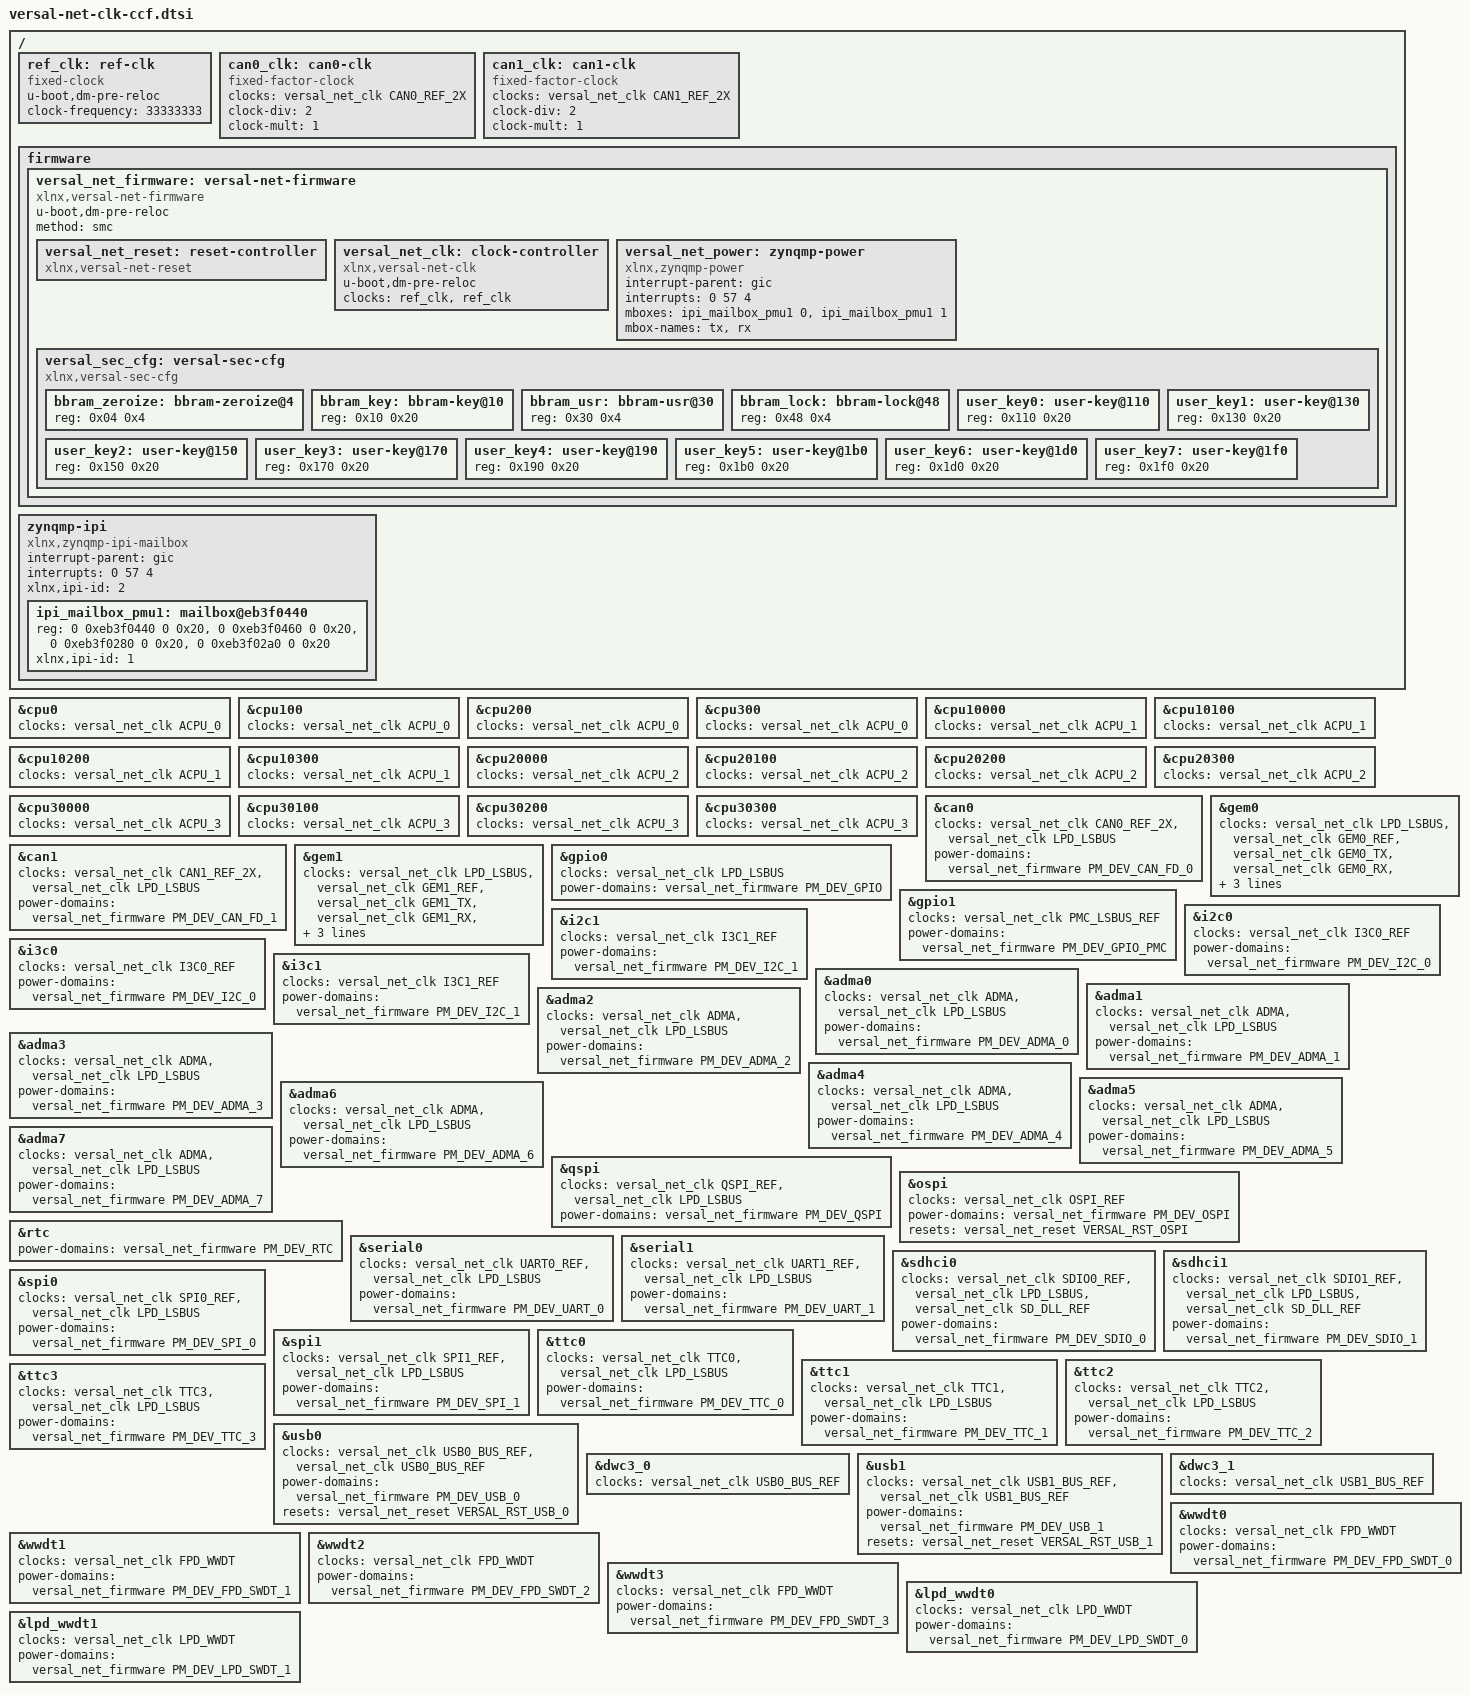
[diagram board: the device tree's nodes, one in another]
// SPDX-License-Identifier: GPL-2.0
/*
 * dts file for Xilinx Versal with PM
 *
 * Copyright (C) 2022, Xilinx, Inc.
 * Copyright (C) 2022, Advanced Micro Devices, Inc.
 *
 * Michal Simek <michal.simek@amd.com>
 */

#include <dt-bindings/clock/xlnx-versal-net-clk.h>
#include <dt-bindings/power/xlnx-versal-net-power.h>
#include <dt-bindings/reset/xlnx-versal-net-resets.h>

/ {
	ref_clk: ref-clk {
		u-boot,dm-pre-reloc;
		compatible = "fixed-clock";
		#clock-cells = <0>;
		clock-frequency = <33333333>;
	};

	can0_clk: can0-clk {
		#clock-cells = <0>;
		compatible = "fixed-factor-clock";
		clocks = <&versal_net_clk CAN0_REF_2X>;
		clock-div = <2>;
		clock-mult = <1>;
	};

	can1_clk: can1-clk {
		#clock-cells = <0>;
		compatible = "fixed-factor-clock";
		clocks = <&versal_net_clk CAN1_REF_2X>;
		clock-div = <2>;
		clock-mult = <1>;
	};

	firmware {
		versal_net_firmware: versal-net-firmware {
			compatible = "xlnx,versal-net-firmware";
			u-boot,dm-pre-reloc;
			method = "smc";
			#power-domain-cells = <1>;

			versal_net_reset: reset-controller {
				compatible = "xlnx,versal-net-reset";
				#reset-cells = <1>;
			};

			versal_net_clk: clock-controller {
				u-boot,dm-pre-reloc;
				#clock-cells = <1>;
				compatible = "xlnx,versal-net-clk";
				clocks = <&ref_clk>, <&ref_clk>;
				clock-names = "ref_clk", "pl_alt_ref_clk";
			};

			versal_net_power: zynqmp-power { /* untested */
				compatible = "xlnx,zynqmp-power";
				interrupt-parent = <&gic>;
				interrupts = <0 57 4>;
				mboxes = <&ipi_mailbox_pmu1 0>,
					 <&ipi_mailbox_pmu1 1>;
				mbox-names = "tx", "rx";
			};

			versal_sec_cfg: versal-sec-cfg { /* untested */
				compatible = "xlnx,versal-sec-cfg";
				#address-cells = <1>;
				#size-cells = <1>;

				bbram_zeroize: bbram-zeroize@4 {
					reg = <0x04 0x4>;
				};

				bbram_key: bbram-key@10 {
					reg = <0x10 0x20>;
				};

				bbram_usr: bbram-usr@30 {
					reg = <0x30 0x4>;
				};

				bbram_lock: bbram-lock@48 {
					reg = <0x48 0x4>;
				};

				user_key0: user-key@110 {
					reg = <0x110 0x20>;
				};

				user_key1: user-key@130 {
					reg = <0x130 0x20>;
				};

				user_key2: user-key@150 {
					reg = <0x150 0x20>;
				};

				user_key3: user-key@170 {
					reg = <0x170 0x20>;
				};

				user_key4: user-key@190 {
					reg = <0x190 0x20>;
				};

				user_key5: user-key@1b0 {
					reg = <0x1b0 0x20>;
				};

				user_key6: user-key@1d0 {
					reg = <0x1d0 0x20>;
				};

				user_key7: user-key@1f0 {
					reg = <0x1f0 0x20>;
				};
			};
		};
	};

	zynqmp-ipi {
		compatible = "xlnx,zynqmp-ipi-mailbox";
		interrupt-parent = <&gic>;
		interrupts = <0 57 4>;
		xlnx,ipi-id = <2>;
		#address-cells = <2>;
		#size-cells = <2>;
		ranges;

		ipi_mailbox_pmu1: mailbox@eb3f0440 {
			reg = <0 0xeb3f0440 0 0x20>,
			      <0 0xeb3f0460 0 0x20>,
			      <0 0xeb3f0280 0 0x20>,
			      <0 0xeb3f02a0 0 0x20>;
			reg-names = "local_request_region", "local_response_region",
				    "remote_request_region", "remote_response_region";
			#mbox-cells = <1>;
			xlnx,ipi-id = <1>;
		};
	};
};

&cpu0 {
	clocks = <&versal_net_clk ACPU_0>;
};

&cpu100 {
	clocks = <&versal_net_clk ACPU_0>;
};

&cpu200 {
	clocks = <&versal_net_clk ACPU_0>;
};

&cpu300 {
	clocks = <&versal_net_clk ACPU_0>;
};

&cpu10000 {
	clocks = <&versal_net_clk ACPU_1>;
};

&cpu10100 {
	clocks = <&versal_net_clk ACPU_1>;
};

&cpu10200 {
	clocks = <&versal_net_clk ACPU_1>;
};

&cpu10300 {
	clocks = <&versal_net_clk ACPU_1>;
};

&cpu20000 {
	clocks = <&versal_net_clk ACPU_2>;
};

&cpu20100 {
	clocks = <&versal_net_clk ACPU_2>;
};

&cpu20200 {
	clocks = <&versal_net_clk ACPU_2>;
};

&cpu20300 {
	clocks = <&versal_net_clk ACPU_2>;
};

&cpu30000 {
	clocks = <&versal_net_clk ACPU_3>;
};

&cpu30100 {
	clocks = <&versal_net_clk ACPU_3>;
};

&cpu30200 {
	clocks = <&versal_net_clk ACPU_3>;
};

&cpu30300 {
	clocks = <&versal_net_clk ACPU_3>;
};

&can0 {
	clocks = <&versal_net_clk CAN0_REF_2X>, <&versal_net_clk LPD_LSBUS>;
	power-domains = <&versal_net_firmware PM_DEV_CAN_FD_0>;
};

&can1 {
	clocks = <&versal_net_clk CAN1_REF_2X>, <&versal_net_clk LPD_LSBUS>;
	power-domains = <&versal_net_firmware PM_DEV_CAN_FD_1>;
};

&gem0 {
	clocks = <&versal_net_clk LPD_LSBUS>,
		 <&versal_net_clk GEM0_REF>, <&versal_net_clk GEM0_TX>,
		 <&versal_net_clk GEM0_RX>, <&versal_net_clk GEM_TSU>;
	power-domains = <&versal_net_firmware PM_DEV_GEM_0>;
};

&gem1 {
	clocks = <&versal_net_clk LPD_LSBUS>,
		 <&versal_net_clk GEM1_REF>, <&versal_net_clk GEM1_TX>,
		 <&versal_net_clk GEM1_RX>, <&versal_net_clk GEM_TSU>;
	power-domains = <&versal_net_firmware PM_DEV_GEM_1>;
};

&gpio0 {
	clocks = <&versal_net_clk LPD_LSBUS>;
	power-domains = <&versal_net_firmware PM_DEV_GPIO>;
};

&gpio1 {
	clocks = <&versal_net_clk PMC_LSBUS_REF>;
	power-domains = <&versal_net_firmware PM_DEV_GPIO_PMC>;
};

&i2c0 {
	clocks = <&versal_net_clk I3C0_REF>;
	power-domains = <&versal_net_firmware PM_DEV_I2C_0>;
};

&i2c1 {
	clocks = <&versal_net_clk I3C1_REF>;
	power-domains = <&versal_net_firmware PM_DEV_I2C_1>;
};

&i3c0 {
	clocks = <&versal_net_clk I3C0_REF>;
	power-domains = <&versal_net_firmware PM_DEV_I2C_0>;
};

&i3c1 {
	clocks = <&versal_net_clk I3C1_REF>;
	power-domains = <&versal_net_firmware PM_DEV_I2C_1>;
};

&adma0 {
	clocks = <&versal_net_clk ADMA>, <&versal_net_clk LPD_LSBUS>;
	power-domains = <&versal_net_firmware PM_DEV_ADMA_0>;
};

&adma1 {
	clocks = <&versal_net_clk ADMA>, <&versal_net_clk LPD_LSBUS>;
	power-domains = <&versal_net_firmware PM_DEV_ADMA_1>;
};

&adma2 {
	clocks = <&versal_net_clk ADMA>, <&versal_net_clk LPD_LSBUS>;
	power-domains = <&versal_net_firmware PM_DEV_ADMA_2>;
};

&adma3 {
	clocks = <&versal_net_clk ADMA>, <&versal_net_clk LPD_LSBUS>;
	power-domains = <&versal_net_firmware PM_DEV_ADMA_3>;
};

&adma4 {
	clocks = <&versal_net_clk ADMA>, <&versal_net_clk LPD_LSBUS>;
	power-domains = <&versal_net_firmware PM_DEV_ADMA_4>;
};

&adma5 {
	clocks = <&versal_net_clk ADMA>, <&versal_net_clk LPD_LSBUS>;
	power-domains = <&versal_net_firmware PM_DEV_ADMA_5>;
};

&adma6 {
	clocks = <&versal_net_clk ADMA>, <&versal_net_clk LPD_LSBUS>;
	power-domains = <&versal_net_firmware PM_DEV_ADMA_6>;
};

&adma7 {
	clocks = <&versal_net_clk ADMA>, <&versal_net_clk LPD_LSBUS>;
	power-domains = <&versal_net_firmware PM_DEV_ADMA_7>;
};

&qspi {
	clocks = <&versal_net_clk QSPI_REF>, <&versal_net_clk LPD_LSBUS>;
	power-domains = <&versal_net_firmware PM_DEV_QSPI>;
};

&ospi {
	clocks = <&versal_net_clk OSPI_REF>;
	power-domains = <&versal_net_firmware PM_DEV_OSPI>;
	resets = <&versal_net_reset VERSAL_RST_OSPI>;
};

&rtc {
	power-domains = <&versal_net_firmware PM_DEV_RTC>;
};

&serial0 {
	clocks = <&versal_net_clk UART0_REF>, <&versal_net_clk LPD_LSBUS>;
	power-domains = <&versal_net_firmware PM_DEV_UART_0>;
};

&serial1 {
	clocks = <&versal_net_clk UART1_REF>, <&versal_net_clk LPD_LSBUS>;
	power-domains = <&versal_net_firmware PM_DEV_UART_1>;
};

&sdhci0 {
	clocks = <&versal_net_clk SDIO0_REF>, <&versal_net_clk LPD_LSBUS>,
		<&versal_net_clk SD_DLL_REF>;
	power-domains = <&versal_net_firmware PM_DEV_SDIO_0>;
};

&sdhci1 {
	clocks = <&versal_net_clk SDIO1_REF>, <&versal_net_clk LPD_LSBUS>,
		<&versal_net_clk SD_DLL_REF>;
	power-domains = <&versal_net_firmware PM_DEV_SDIO_1>;
};

&spi0 {
	clocks = <&versal_net_clk SPI0_REF>, <&versal_net_clk LPD_LSBUS>;
	power-domains = <&versal_net_firmware PM_DEV_SPI_0>;
};

&spi1 {
	clocks = <&versal_net_clk SPI1_REF>, <&versal_net_clk LPD_LSBUS>;
	power-domains = <&versal_net_firmware PM_DEV_SPI_1>;
};

&ttc0 {
	clocks = <&versal_net_clk TTC0>, <&versal_net_clk LPD_LSBUS>;
	power-domains = <&versal_net_firmware PM_DEV_TTC_0>;
};

&ttc1 {
	clocks = <&versal_net_clk TTC1>, <&versal_net_clk LPD_LSBUS>;
	power-domains = <&versal_net_firmware PM_DEV_TTC_1>;
};

&ttc2 {
	clocks = <&versal_net_clk TTC2>, <&versal_net_clk LPD_LSBUS>;
	power-domains = <&versal_net_firmware PM_DEV_TTC_2>;
};

&ttc3 {
	clocks = <&versal_net_clk TTC3>, <&versal_net_clk LPD_LSBUS>;
	power-domains = <&versal_net_firmware PM_DEV_TTC_3>;
};

&usb0 {
	clocks = <&versal_net_clk USB0_BUS_REF>, <&versal_net_clk USB0_BUS_REF>;
	power-domains = <&versal_net_firmware PM_DEV_USB_0>;
	resets = <&versal_net_reset VERSAL_RST_USB_0>;
};

&dwc3_0 {
	clocks = <&versal_net_clk USB0_BUS_REF>;
};

&usb1 {
	clocks = <&versal_net_clk USB1_BUS_REF>, <&versal_net_clk USB1_BUS_REF>;
	power-domains = <&versal_net_firmware PM_DEV_USB_1>;
	resets = <&versal_net_reset VERSAL_RST_USB_1>;
};

&dwc3_1 {
	clocks = <&versal_net_clk USB1_BUS_REF>;
};

&wwdt0 {
	clocks = <&versal_net_clk FPD_WWDT>;
	power-domains = <&versal_net_firmware PM_DEV_FPD_SWDT_0>;
};

&wwdt1 {
	clocks = <&versal_net_clk FPD_WWDT>;
	power-domains = <&versal_net_firmware PM_DEV_FPD_SWDT_1>;
};

&wwdt2 {
	clocks = <&versal_net_clk FPD_WWDT>;
	power-domains = <&versal_net_firmware PM_DEV_FPD_SWDT_2>;
};

&wwdt3 {
	clocks = <&versal_net_clk FPD_WWDT>;
	power-domains = <&versal_net_firmware PM_DEV_FPD_SWDT_3>;
};

&lpd_wwdt0 {
	clocks = <&versal_net_clk LPD_WWDT>;
	power-domains = <&versal_net_firmware PM_DEV_LPD_SWDT_0>;
};

&lpd_wwdt1 {
	clocks = <&versal_net_clk LPD_WWDT>;
	power-domains = <&versal_net_firmware PM_DEV_LPD_SWDT_1>;
};
